CM_ "IMPORT _comma.dbc";
CM_ "IMPORT _honda_common.dbc";
CM_ "IMPORT _bosch_2018.dbc";
CM_ "IMPORT _steering_sensors_a.dbc";

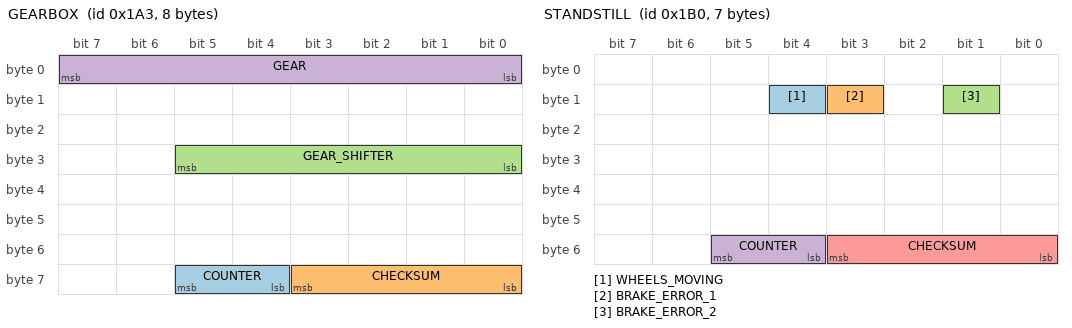
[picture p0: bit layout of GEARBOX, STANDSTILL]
BO_ 419 GEARBOX: 8 PCM
 SG_ COUNTER : 61|2@0+ (1,0) [0|3] "" EON
 SG_ CHECKSUM : 59|4@0+ (1,0) [0|3] "" EON
 SG_ GEAR_SHIFTER : 29|6@0+ (1,0) [0|63] "" EON
 SG_ GEAR : 7|8@0+ (1,0) [0|255] "" EON

BO_ 432 STANDSTILL: 7 VSA
 SG_ WHEELS_MOVING : 12|1@0+ (1,0) [0|1] "" EON
 SG_ BRAKE_ERROR_1 : 11|1@0+ (1,0) [0|1] "" EON
 SG_ BRAKE_ERROR_2 : 9|1@0+ (1,0) [0|1] "" EON
 SG_ COUNTER : 53|2@0+ (1,0) [0|3] "" EON
 SG_ CHECKSUM : 51|4@0+ (1,0) [0|15] "" EON

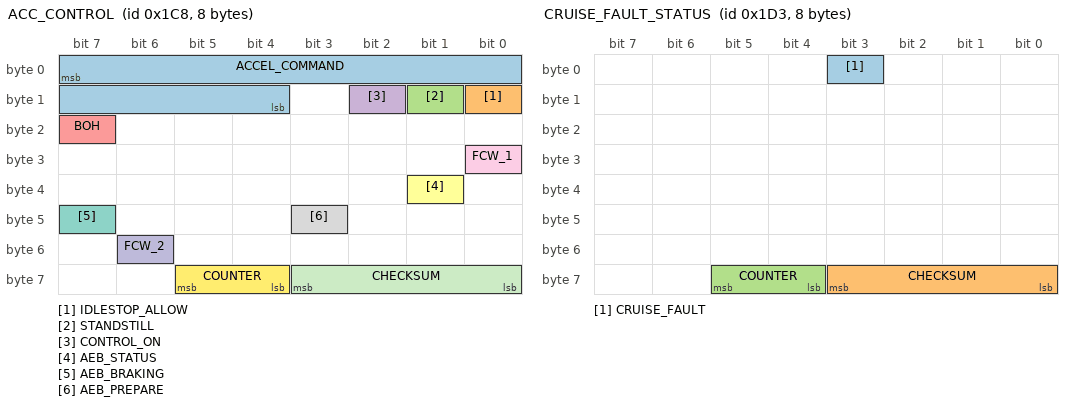
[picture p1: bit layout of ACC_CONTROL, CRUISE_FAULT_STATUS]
BO_ 456 ACC_CONTROL: 8 XXX
 SG_ ACCEL_COMMAND : 7|12@0- (0.01,0) [0|0] "m/s^2" XXX
 SG_ IDLESTOP_ALLOW : 8|1@0+ (1,0) [0|1] "" XXX
 SG_ STANDSTILL : 9|1@0+ (1,0) [0|1] "" XXX
 SG_ CONTROL_ON : 10|1@0+ (1,0) [0|1] "" XXX
 SG_ BOH : 23|1@0+ (1,0) [0|1] "" XXX
 SG_ AEB_STATUS : 33|1@1+ (1,0) [0|7] "" XXX
 SG_ AEB_BRAKING : 47|1@0+ (1,0) [0|1] "" XXX
 SG_ AEB_PREPARE : 43|1@0+ (1,0) [0|1] "" XXX
 SG_ FCW_1 : 24|1@1+ (1,0) [0|3] "" XXX
 SG_ FCW_2 : 54|1@0+ (1,0) [0|3] "" XXX
 SG_ CHECKSUM : 59|4@0+ (1,0) [0|15] "" XXX
 SG_ COUNTER : 61|2@0+ (1,0) [0|3] "" XXX

BO_ 467 CRUISE_FAULT_STATUS: 8 XXX
 SG_ CRUISE_FAULT : 3|1@0+ (1,0) [0|1] "" XXX
 SG_ CHECKSUM : 59|4@0+ (1,0) [0|15] "" XXX
 SG_ COUNTER : 61|2@0+ (1,0) [0|3] "" XXX

BO_ 829 LKAS_HUD: 8 ADAS
 SG_ CAM_TEMP_HIGH : 7|1@0+ (1,0) [0|255] "" BDY
 SG_ SET_ME_X41 : 6|7@0+ (1,0) [0|127] "" BDY
 SG_ BOH : 6|7@0+ (1,0) [0|127] "" BDY
 SG_ DASHED_LANES : 14|1@0+ (1,0) [0|1] "" BDY
 SG_ DTC : 13|1@0+ (1,0) [0|1] "" BDY
 SG_ LKAS_PROBLEM : 12|1@0+ (1,0) [0|1] "" BDY
 SG_ LKAS_OFF : 11|1@0+ (1,0) [0|1] "" BDY
 SG_ SOLID_LANES : 10|1@0+ (1,0) [0|1] "" BDY
 SG_ LDW_RIGHT : 9|1@0+ (1,0) [0|1] "" BDY
 SG_ STEERING_REQUIRED : 8|1@0+ (1,0) [0|1] "" BDY
 SG_ BOH_2 : 23|2@0+ (1,0) [0|4] "" BDY
 SG_ LDW_PROBLEM : 21|1@0+ (1,0) [0|1] "" BDY
 SG_ BEEP : 17|2@0+ (1,0) [0|1] "" BDY
 SG_ LDW_ON : 28|1@0+ (1,0) [0|1] "" BDY
 SG_ LDW_OFF : 27|1@0+ (1,0) [0|1] "" BDY
 SG_ CLEAN_WINDSHIELD : 26|1@0+ (1,0) [0|1] "" BDY
 SG_ SET_ME_X48 : 31|8@0+ (1,0) [0|255] "" BDY
 SG_ LANE_LINES : 36|2@0+ (1,0) [0|3] "" BDY
 SG_ COUNTER : 61|2@0+ (1,0) [0|3] "" BDY
 SG_ CHECKSUM : 59|4@0+ (1,0) [0|15] "" BDY

VAL_ 419 GEAR_SHIFTER  32 "D" 16 "N" 8 "R" 4 "P" 0 "B" ;
